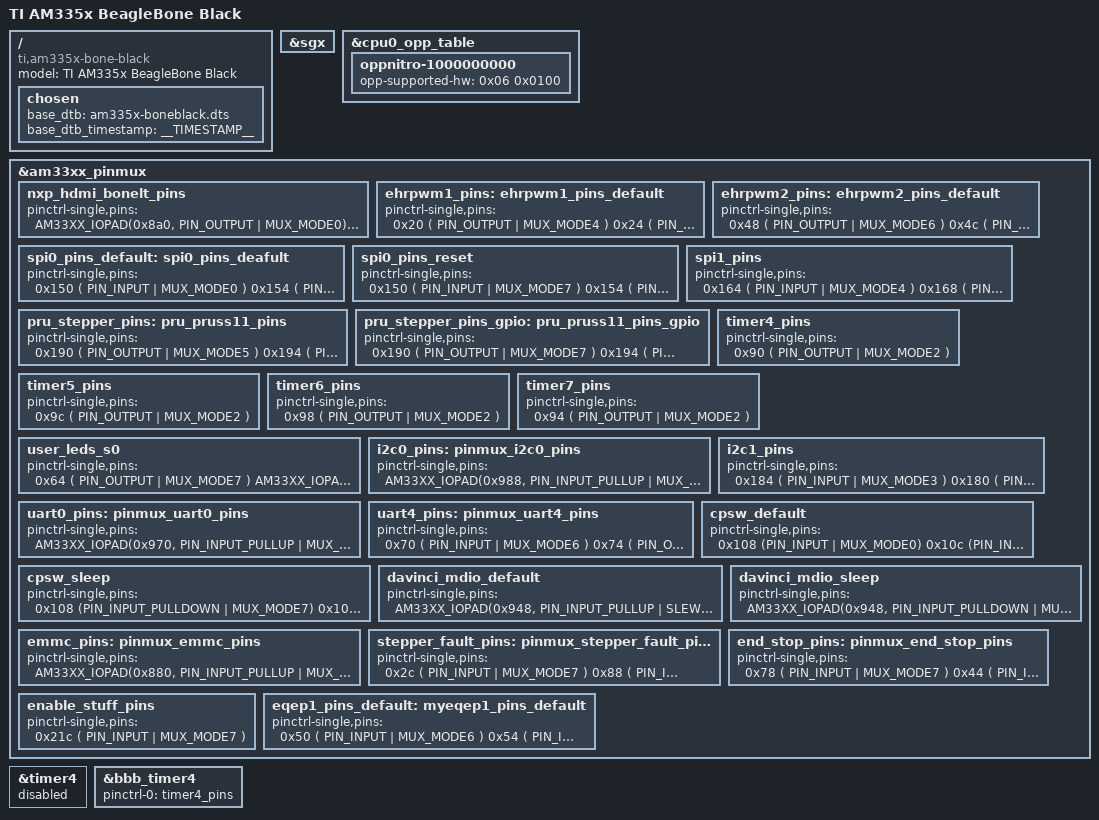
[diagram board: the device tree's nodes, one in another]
// SPDX-License-Identifier: GPL-2.0-only
/*
 * Copyright (C) 2012 Texas Instruments Incorporated - http://www.ti.com/
 */
/dts-v1/;

#include "am33xx.dtsi"
#include "am335x-bone-common.dtsi"
#include "am335x-boneblack-common.dtsi"
/* #include "am335x-bone-jtag.dtsi" */

/ {
	model = "TI AM335x BeagleBone Black";
	compatible = "ti,am335x-bone-black", "ti,am335x-bone", "ti,am33xx";

	chosen {
		base_dtb = "am335x-boneblack.dts";
		base_dtb_timestamp = __TIMESTAMP__;
	};
};

&sgx {
	status = "okay";
};

&cpu0_opp_table {
	/*
	 * All PG 2.0 silicon may not support 1GHz but some of the early
	 * BeagleBone Blacks have PG 2.0 silicon which is guaranteed
	 * to support 1GHz OPP so enable it for PG 2.0 on this board.
	 */
	oppnitro-1000000000 {
		opp-supported-hw = <0x06 0x0100>;
	};
};

&am33xx_pinmux {
	nxp_hdmi_bonelt_pins: nxp_hdmi_bonelt_pins {
		pinctrl-single,pins = <
			AM33XX_IOPAD(0x8a0, PIN_OUTPUT | MUX_MODE0)		/* lcd_data0.lcd_data0 */
			AM33XX_IOPAD(0x8a4, PIN_OUTPUT | MUX_MODE0)		/* lcd_data1.lcd_data1 */
			AM33XX_IOPAD(0x8a8, PIN_OUTPUT | MUX_MODE0)		/* lcd_data2.lcd_data2 */
			AM33XX_IOPAD(0x8ac, PIN_OUTPUT | MUX_MODE0)		/* lcd_data3.lcd_data3 */
			AM33XX_IOPAD(0x8b0, PIN_OUTPUT | MUX_MODE0)		/* lcd_data4.lcd_data4 */
			AM33XX_IOPAD(0x8b4, PIN_OUTPUT | MUX_MODE0)		/* lcd_data5.lcd_data5 */
			AM33XX_IOPAD(0x8b8, PIN_OUTPUT | MUX_MODE0)		/* lcd_data6.lcd_data6 */
			AM33XX_IOPAD(0x8bc, PIN_OUTPUT | MUX_MODE0)		/* lcd_data7.lcd_data7 */
			AM33XX_IOPAD(0x8c0, PIN_OUTPUT | MUX_MODE0)		/* lcd_data8.lcd_data8 */
			AM33XX_IOPAD(0x8c4, PIN_OUTPUT | MUX_MODE0)		/* lcd_data9.lcd_data9 */
			AM33XX_IOPAD(0x8c8, PIN_OUTPUT | MUX_MODE0)		/* lcd_data10.lcd_data10 */
			AM33XX_IOPAD(0x8cc, PIN_OUTPUT | MUX_MODE0)		/* lcd_data11.lcd_data11 */
			AM33XX_IOPAD(0x8d0, PIN_OUTPUT | MUX_MODE0)		/* lcd_data12.lcd_data12 */
			AM33XX_IOPAD(0x8d4, PIN_OUTPUT | MUX_MODE0)		/* lcd_data13.lcd_data13 */
			AM33XX_IOPAD(0x8d8, PIN_OUTPUT | MUX_MODE0)		/* lcd_data14.lcd_data14 */
			AM33XX_IOPAD(0x8dc, PIN_OUTPUT | MUX_MODE0)		/* lcd_data15.lcd_data15 */
			AM33XX_IOPAD(0x8e0, PIN_OUTPUT_PULLDOWN | MUX_MODE0)	/* lcd_vsync.lcd_vsync */
			AM33XX_IOPAD(0x8e4, PIN_OUTPUT_PULLDOWN | MUX_MODE0)	/* lcd_hsync.lcd_hsync */
			AM33XX_IOPAD(0x8e8, PIN_OUTPUT_PULLDOWN | MUX_MODE0)	/* lcd_pclk.lcd_pclk */
			AM33XX_IOPAD(0x8ec, PIN_OUTPUT_PULLDOWN | MUX_MODE0)	/* lcd_ac_bias_en.lcd_ac_bias_en */
		>;
	};

    ehrpwm1_pins: ehrpwm1_pins_default {
	    pinctrl-single,pins = <
		    0x20 ( PIN_OUTPUT | MUX_MODE4 ) /* (U10) gpmc_ad8.ehrpwm2A */
		    0x24 ( PIN_OUTPUT | MUX_MODE4 ) /* (T10) gpmc_ad9.ehrpwm2B */
	    >;
    };

    ehrpwm2_pins: ehrpwm2_pins_default {
	    pinctrl-single,pins = <
		    0x48 ( PIN_OUTPUT | MUX_MODE6 ) /* (U14) gpmc_a2.ehrpwm1A */
		    0x4c ( PIN_OUTPUT | MUX_MODE6 ) /* (T14) gpmc_a3.ehrpwm1B */
	    >;
    };

    spi0_pins_default: spi0_pins_deafult {
	    pinctrl-single,pins = <
		    0x150 ( PIN_INPUT | MUX_MODE0 ) /* (A17) spi0_sclk.spi0_sclk */
		    0x154 ( PIN_INPUT | MUX_MODE0 ) /* (B17) spi0_d0.spi0_d0 */
		    0x158 ( PIN_INPUT | MUX_MODE0 ) /* (B16) spi0_d1.spi0_d1 */
		    0x15c ( PIN_OUTPUT | MUX_MODE0 ) /* (A16) spi0_cs0.spi0_cs0 */
		    0x160 ( PIN_OUTPUT | MUX_MODE0 ) /* (C15) spi0_cs1.spi0_cs1 */
	    >;
    };

    spi0_pins_reset: spi0_pins_reset {
	    pinctrl-single,pins = <
		    0x150 ( PIN_INPUT | MUX_MODE7 ) /* (A17) spi0_sclk.spi0_sclk */
		    0x154 ( PIN_INPUT | MUX_MODE7 ) /* (B17) spi0_d0.spi0_d0 */
		    0x158 ( PIN_INPUT | MUX_MODE7 ) /* (B16) spi0_d1.spi0_d1 */
		    0x15c ( PIN_INPUT | MUX_MODE7 ) /* (A16) spi0_cs0.spi0_cs0 */
		    0x160 ( PIN_INPUT | MUX_MODE7 ) /* (C15) spi0_cs1.spi0_cs1 */
	    >;
    };

    spi1_pins: spi1_pins {
	    pinctrl-single,pins = <
		    0x164 ( PIN_INPUT | MUX_MODE4 ) /* (C18) eCAP0_in_PWM0_out.spi1_sclk */
		    0x168 ( PIN_INPUT | MUX_MODE4 ) /* (E18) uart0_ctsn.spi1_d0 */
		    0x16c ( PIN_INPUT | MUX_MODE4 ) /* (E17) uart0_rtsn.spi1_d1 */
		    0x178 ( PIN_INPUT | MUX_MODE4 ) /* (D18) uart1_ctsn.spi1_cs0 */
		    0x17c ( PIN_INPUT | MUX_MODE4 ) /* (D17) uart1_rtsn.spi1_cs1 */
	    >;
    };

    pru_stepper_pins: pru_pruss11_pins {
	    pinctrl-single,pins = <
		    0x190 ( PIN_OUTPUT | MUX_MODE5 ) /* (A13) mcasp0_aclkx.pr1_pru0_pru_r30[0] */
		    0x194 ( PIN_OUTPUT | MUX_MODE5 ) /* (B13) mcasp0_fsx.pr1_pru0_pru_r30[1] */
		    0x198 ( PIN_OUTPUT | MUX_MODE5 ) /* (D12) mcasp0_axr0.pr1_pru0_pru_r30[2] */
		    0x19c ( PIN_OUTPUT | MUX_MODE5 ) /* (C12) mcasp0_ahclkr.pr1_pru0_pru_r30[3] */
		    0x1a0 ( PIN_OUTPUT | MUX_MODE5 ) /* (B12) mcasp0_aclkr.pr1_pru0_pru_r30[4] */
		    0x1a4 ( PIN_OUTPUT | MUX_MODE5 ) /* (C13) mcasp0_fsr.pr1_pru0_pru_r30[5] */
		    0x1a8 ( PIN_OUTPUT | MUX_MODE5 ) /* (D13) mcasp0_axr1.pr1_pru0_pru_r30[6] */
		    0x1ac ( PIN_OUTPUT | MUX_MODE5 ) /* (A14) mcasp0_ahclkx.pr1_pru0_pru_r30[7] */
		    0xf0 ( PIN_OUTPUT | MUX_MODE5 ) /* (F17) mmc0_dat3.pr1_pru0_pru_r30[8] */
		    0xf4 ( PIN_OUTPUT | MUX_MODE5 ) /* (F18) mmc0_dat2.pr1_pru0_pru_r30[9] */
		    0xf8 ( PIN_OUTPUT | MUX_MODE5 ) /* (G15) mmc0_dat1.pr1_pru0_pru_r30[10] */
		    0xfc ( PIN_OUTPUT | MUX_MODE5 ) /* (G16) mmc0_dat0.pr1_pru0_pru_r30[11] */
		    0x100 ( PIN_OUTPUT | MUX_MODE5 ) /* (G17) mmc0_clk.pr1_pru0_pru_r30[12] */
		    0x104 ( PIN_OUTPUT | MUX_MODE5 ) /* (G18) mmc0_cmd.pr1_pru0_pru_r30[13] */
		    0x30 ( PIN_OUTPUT | MUX_MODE6 ) /* (T12) gpmc_ad12.pr1_pru0_pru_r30[14] */
		    0x34 ( PIN_OUTPUT | MUX_MODE6 ) /* (R12) gpmc_ad13.pr1_pru0_pru_r30[15] */
		    /*0x38 ( PIN_INPUT | MUX_MODE6 )*/ /* (V13) gpmc_ad14.pr1_pru0_pru_r31[14] */
		    /*0x3c ( PIN_INPUT | MUX_MODE6 )*/ /* (U13) gpmc_ad15.pr1_pru0_pru_r31[15] */
		    0x1b4 ( PIN_INPUT | MUX_MODE5 ) /* (D14) xdma_event_intr1.pr1_pru0_pru_r31[16] */
	    >;
    };

    pru_stepper_pins_gpio: pru_pruss11_pins_gpio {
	    pinctrl-single,pins = <
		    0x190 ( PIN_OUTPUT | MUX_MODE7 ) /* (A13) mcasp0_aclkx.pr1_pru0_pru_r30[0] */
		    0x194 ( PIN_OUTPUT | MUX_MODE7 ) /* (B13) mcasp0_fsx.pr1_pru0_pru_r30[1] */
		    0x198 ( PIN_OUTPUT | MUX_MODE7 ) /* (D12) mcasp0_axr0.pr1_pru0_pru_r30[2] */
		    0x19c ( PIN_OUTPUT | MUX_MODE7 ) /* (C12) mcasp0_ahclkr.pr1_pru0_pru_r30[3] */
		    0x1a0 ( PIN_OUTPUT | MUX_MODE7 ) /* (B12) mcasp0_aclkr.pr1_pru0_pru_r30[4] */
		    0x1a4 ( PIN_OUTPUT | MUX_MODE7 ) /* (C13) mcasp0_fsr.pr1_pru0_pru_r30[5] */
		    0x1a8 ( PIN_OUTPUT | MUX_MODE7 ) /* (D13) mcasp0_axr1.pr1_pru0_pru_r30[6] */
		    0x1ac ( PIN_OUTPUT | MUX_MODE7 ) /* (A14) mcasp0_ahclkx.pr1_pru0_pru_r30[7] */
		    0xf0 ( PIN_OUTPUT | MUX_MODE7 ) /* (F17) mmc0_dat3.pr1_pru0_pru_r30[8] */
		    0xf4 ( PIN_OUTPUT | MUX_MODE7 ) /* (F18) mmc0_dat2.pr1_pru0_pru_r30[9] */
		    0xf8 ( PIN_OUTPUT | MUX_MODE7 ) /* (G15) mmc0_dat1.pr1_pru0_pru_r30[10] */
		    0xfc ( PIN_OUTPUT | MUX_MODE7 ) /* (G16) mmc0_dat0.pr1_pru0_pru_r30[11] */
		    0x100 ( PIN_OUTPUT | MUX_MODE7 ) /* (G17) mmc0_clk.pr1_pru0_pru_r30[12] */
		    0x104 ( PIN_OUTPUT | MUX_MODE7 ) /* (G18) mmc0_cmd.pr1_pru0_pru_r30[13] */
		    0x30 ( PIN_OUTPUT | MUX_MODE7 ) /* (T12) gpmc_ad12.pr1_pru0_pru_r30[14] */
		    0x34 ( PIN_OUTPUT | MUX_MODE7 ) /* (R12) gpmc_ad13.pr1_pru0_pru_r30[15] */
	    >;
    };

    timer4_pins: timer4_pins {
	    pinctrl-single,pins = <
		    0x90 ( PIN_OUTPUT | MUX_MODE2 ) /* (R7) gpmc_advn_ale.timer4 */
	    >;
    };

    timer5_pins: timer5_pins {
	    pinctrl-single,pins = <
		     0x9c ( PIN_OUTPUT | MUX_MODE2 ) /* (T6) gpmc_be0n_cle.timer5 */
	    >;
    };
    timer6_pins: timer6_pins {
	    pinctrl-single,pins = <
		    0x98 ( PIN_OUTPUT | MUX_MODE2 ) /* (U6) gpmc_wen.timer6 */
	    >;
    };
    timer7_pins: timer7_pins {
	    pinctrl-single,pins = <
		     0x94 ( PIN_OUTPUT | MUX_MODE2 ) /* (T7) gpmc_oen_ren.timer7 */
	    >;
    };

    user_leds_s0: user_leds_s0 {
		pinctrl-single,pins = <
            0x64 ( PIN_OUTPUT | MUX_MODE7 ) /* (U16) gpmc_a9.gpio1[25] */
			AM33XX_IOPAD(0x858, PIN_OUTPUT | MUX_MODE7)	/* gpmc_a6.gpio1_22 */
			AM33XX_IOPAD(0x85c, PIN_OUTPUT | MUX_MODE7)	/* gpmc_a7.gpio1_23 */
			AM33XX_IOPAD(0x860, PIN_OUTPUT | MUX_MODE7)	/* gpmc_a8.gpio1_24 */
		>;
	};

    i2c0_pins: pinmux_i2c0_pins {
		pinctrl-single,pins = <
			AM33XX_IOPAD(0x988, PIN_INPUT_PULLUP | MUX_MODE0)	/* i2c0_sda.i2c0_sda */
			AM33XX_IOPAD(0x98c, PIN_INPUT_PULLUP | MUX_MODE0)	/* i2c0_scl.i2c0_scl */
		>;
	};

    i2c1_pins: i2c1_pins {
        pinctrl-single,pins = <
	        0x184 ( PIN_INPUT | MUX_MODE3 ) /* (D15) uart1_txd.I2C1_SCL */
	        0x180 ( PIN_INPUT | MUX_MODE3 ) /* (D16) uart1_rxd.I2C1_SDA */
        >;
    };


    uart0_pins: pinmux_uart0_pins {
		pinctrl-single,pins = <
			AM33XX_IOPAD(0x970, PIN_INPUT_PULLUP | MUX_MODE0)	/* uart0_rxd.uart0_rxd */
			AM33XX_IOPAD(0x974, PIN_OUTPUT_PULLDOWN | MUX_MODE0)	/* uart0_txd.uart0_txd */
		>;
	};

    uart4_pins: pinmux_uart4_pins {
	    pinctrl-single,pins = <
		    0x70 ( PIN_INPUT | MUX_MODE6 ) /* (T17) gpmc_wait0.uart4_rxd */
		    0x74 ( PIN_OUTPUT | MUX_MODE6 ) /* (U17) gpmc_wpn.uart4_txd */
	    >;
    };

    cpsw_default: cpsw_default {
		pinctrl-single,pins = <
			/* Slave 1 */
			0x108 (PIN_INPUT | MUX_MODE0)		/* mii1_col.mii1_col */
			0x10c (PIN_INPUT | MUX_MODE0)		/* mii1_crs.mii1_crs */
			AM33XX_IOPAD(0x910, PIN_INPUT_PULLUP | MUX_MODE0)	/* mii1_rxerr.mii1_rxerr */
			AM33XX_IOPAD(0x914, PIN_OUTPUT_PULLDOWN | MUX_MODE0)	/* mii1_txen.mii1_txen */
			AM33XX_IOPAD(0x918, PIN_INPUT_PULLUP | MUX_MODE0)	/* mii1_rxdv.mii1_rxdv */
			AM33XX_IOPAD(0x91c, PIN_OUTPUT_PULLDOWN | MUX_MODE0)	/* mii1_txd3.mii1_txd3 */
			AM33XX_IOPAD(0x920, PIN_OUTPUT_PULLDOWN | MUX_MODE0)	/* mii1_txd2.mii1_txd2 */
			AM33XX_IOPAD(0x924, PIN_OUTPUT_PULLDOWN | MUX_MODE0)	/* mii1_txd1.mii1_txd1 */
			AM33XX_IOPAD(0x928, PIN_OUTPUT_PULLDOWN | MUX_MODE0)	/* mii1_txd0.mii1_txd0 */
			AM33XX_IOPAD(0x92c, PIN_INPUT_PULLUP | MUX_MODE0)	/* mii1_txclk.mii1_txclk */
			AM33XX_IOPAD(0x930, PIN_INPUT_PULLUP | MUX_MODE0)	/* mii1_rxclk.mii1_rxclk */
			AM33XX_IOPAD(0x934, PIN_INPUT_PULLUP | MUX_MODE0)	/* mii1_rxd3.mii1_rxd3 */
			AM33XX_IOPAD(0x938, PIN_INPUT_PULLUP | MUX_MODE0)	/* mii1_rxd2.mii1_rxd2 */
			AM33XX_IOPAD(0x93c, PIN_INPUT_PULLUP | MUX_MODE0)	/* mii1_rxd1.mii1_rxd1 */
			AM33XX_IOPAD(0x940, PIN_INPUT_PULLUP | MUX_MODE0)	/* mii1_rxd0.mii1_rxd0 */
		>;
	};

	cpsw_sleep: cpsw_sleep {
		pinctrl-single,pins = <
			/* Slave 1 reset value */
			0x108 (PIN_INPUT_PULLDOWN | MUX_MODE7)
			0x10c (PIN_INPUT_PULLDOWN | MUX_MODE7)
			AM33XX_IOPAD(0x910, PIN_INPUT_PULLDOWN | MUX_MODE7)
			AM33XX_IOPAD(0x914, PIN_INPUT_PULLDOWN | MUX_MODE7)
			AM33XX_IOPAD(0x918, PIN_INPUT_PULLDOWN | MUX_MODE7)
			AM33XX_IOPAD(0x91c, PIN_INPUT_PULLDOWN | MUX_MODE7)
			AM33XX_IOPAD(0x920, PIN_INPUT_PULLDOWN | MUX_MODE7)
			AM33XX_IOPAD(0x924, PIN_INPUT_PULLDOWN | MUX_MODE7)
			AM33XX_IOPAD(0x928, PIN_INPUT_PULLDOWN | MUX_MODE7)
			AM33XX_IOPAD(0x92c, PIN_INPUT_PULLDOWN | MUX_MODE7)
			AM33XX_IOPAD(0x930, PIN_INPUT_PULLDOWN | MUX_MODE7)
			AM33XX_IOPAD(0x934, PIN_INPUT_PULLDOWN | MUX_MODE7)
			AM33XX_IOPAD(0x938, PIN_INPUT_PULLDOWN | MUX_MODE7)
			AM33XX_IOPAD(0x93c, PIN_INPUT_PULLDOWN | MUX_MODE7)
			AM33XX_IOPAD(0x940, PIN_INPUT_PULLDOWN | MUX_MODE7)
		>;
	};

	davinci_mdio_default: davinci_mdio_default {
		pinctrl-single,pins = <
			/* MDIO */
			AM33XX_IOPAD(0x948, PIN_INPUT_PULLUP | SLEWCTRL_FAST | MUX_MODE0)	/* mdio_data.mdio_data */
			AM33XX_IOPAD(0x94c, PIN_OUTPUT_PULLUP | MUX_MODE0)			/* mdio_clk.mdio_clk */
		>;
	};

	davinci_mdio_sleep: davinci_mdio_sleep {
		pinctrl-single,pins = <
			/* MDIO reset value */
			AM33XX_IOPAD(0x948, PIN_INPUT_PULLDOWN | MUX_MODE7)
			AM33XX_IOPAD(0x94c, PIN_INPUT_PULLDOWN | MUX_MODE7)
		>;
	};

	emmc_pins: pinmux_emmc_pins {
		pinctrl-single,pins = <
			AM33XX_IOPAD(0x880, PIN_INPUT_PULLUP | MUX_MODE2) /* gpmc_csn1.mmc1_clk */
			AM33XX_IOPAD(0x884, PIN_INPUT_PULLUP | MUX_MODE2) /* gpmc_csn2.mmc1_cmd */
			AM33XX_IOPAD(0x800, PIN_INPUT_PULLUP | MUX_MODE1) /* gpmc_ad0.mmc1_dat0 */
			AM33XX_IOPAD(0x804, PIN_INPUT_PULLUP | MUX_MODE1) /* gpmc_ad1.mmc1_dat1 */
			AM33XX_IOPAD(0x808, PIN_INPUT_PULLUP | MUX_MODE1) /* gpmc_ad2.mmc1_dat2 */
			AM33XX_IOPAD(0x80c, PIN_INPUT_PULLUP | MUX_MODE1) /* gpmc_ad3.mmc1_dat3 */
			AM33XX_IOPAD(0x810, PIN_INPUT_PULLUP | MUX_MODE1) /* gpmc_ad4.mmc1_dat4 */
			AM33XX_IOPAD(0x814, PIN_INPUT_PULLUP | MUX_MODE1) /* gpmc_ad5.mmc1_dat5 */
			AM33XX_IOPAD(0x818, PIN_INPUT_PULLUP | MUX_MODE1) /* gpmc_ad6.mmc1_dat6 */
			AM33XX_IOPAD(0x81c, PIN_INPUT_PULLUP | MUX_MODE1) /* gpmc_ad7.mmc1_dat7 */
		>;
	};

    stepper_fault_pins: pinmux_stepper_fault_pins{
        pinctrl-single,pins = <
            0x2c  ( PIN_INPUT | MUX_MODE7 ) // FAULT X
            0x88  ( PIN_INPUT | MUX_MODE7 ) // FAULT Y
            0x40  ( PIN_INPUT | MUX_MODE7 ) // FAULT Z
            0x8c  ( PIN_INPUT | MUX_MODE7 ) // FAULT E
            0x144 ( PIN_INPUT | MUX_MODE7 ) // FAULT H
            0x28  ( PIN_INPUT | MUX_MODE7 ) // FAULT A
        >;
    };

    end_stop_pins: pinmux_end_stop_pins{
        pinctrl-single,pins = <
            0x78 ( PIN_INPUT | MUX_MODE7 ) // End stop X1  = GPIO3_21
            0x44 ( PIN_INPUT | MUX_MODE7 ) // End stop X2  = GPIO0_30
            0x6c ( PIN_INPUT | MUX_MODE7 ) // End stop Y1  = GPIO1_27
            0x7c ( PIN_INPUT | MUX_MODE7 ) // End stop Z1  = GPIO1_14
            0x38 ( PIN_INPUT | MUX_MODE7 ) // End stop Z2  = GPIO1_15
            0x3c ( PIN_INPUT | MUX_MODE7 ) // End stop Y2  = GPIO3_17
        >;
    };

    enable_stuff_pins: enable_stuff_pins{
        pinctrl-single,pins = <
	            0x21c ( PIN_INPUT | MUX_MODE7 ) /* (F16) USB0_DRVVBUS.gpio0[18] */
        >;
    };

    eqep1_pins_default: myeqep1_pins_default {
	    pinctrl-single,pins = <
		    0x50 ( PIN_INPUT | MUX_MODE6 ) /* (R14) gpmc_a4.eQEP1A_in */
		    0x54 ( PIN_INPUT | MUX_MODE6 ) /* (V15) gpmc_a5.eQEP1B_in */
	    >;
    };
};

&timer4 {
	status = "disabled";
	/delete-property/ ti,hwmods;
};

&bbb_timer4 {
    pinctrl-names = "default";
    pinctrl-0 = <&timer4_pins>;
    status = "okay";
};
